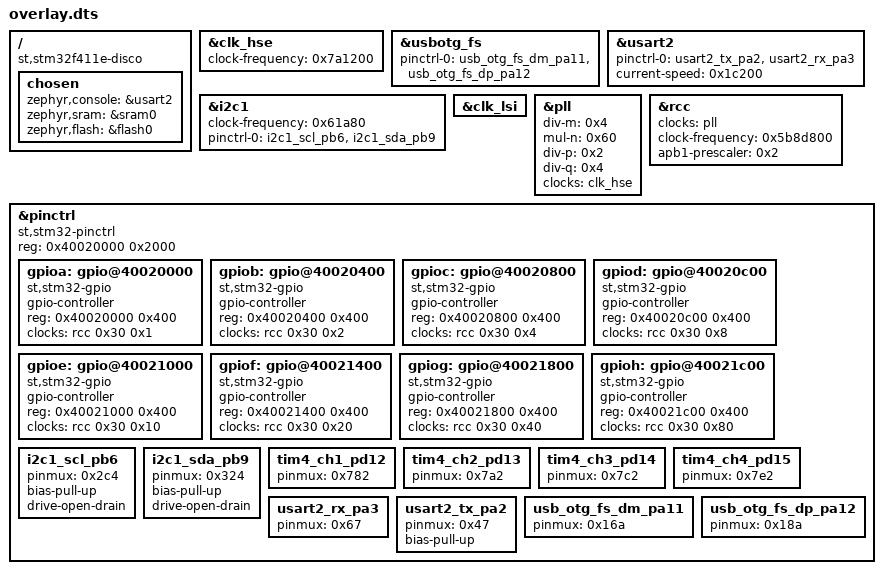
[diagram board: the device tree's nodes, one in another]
/ {
	compatible = "st,stm32f411e-disco";
	chosen {
		zephyr,console = &usart2;
		zephyr,sram = &sram0;
		zephyr,flash = &flash0;
	};
};
&clk_hse{
	status = "okay";
	clock-frequency = < 0x7a1200 >;
};
&usbotg_fs{
	status = "okay";
	pinctrl-0 = < &usb_otg_fs_dm_pa11 &usb_otg_fs_dp_pa12 >;
	pinctrl-names = "default";
};
&usart2{
	status = "okay";
	pinctrl-0 = < &usart2_tx_pa2 &usart2_rx_pa3 >;
	pinctrl-names = "default";
	current-speed = < 0x1c200 >;
};
&i2c1{
	clock-frequency = < 0x61a80 >;
	status = "okay";
	pinctrl-0 = < &i2c1_scl_pb6 &i2c1_sda_pb9 >;
	pinctrl-names = "default";
};
&clk_lsi{
	status = "okay";
};
&pll{
	status = "okay";
	div-m = < 0x4 >;
	mul-n = < 0x60 >;
	div-p = < 0x2 >;
	div-q = < 0x4 >;
	clocks = < &clk_hse >;
};
&rcc{
	clocks = < &pll >;
	clock-frequency = < 0x5b8d800 >;
	apb1-prescaler = < 0x2 >;
};
&pinctrl{
	compatible = "st,stm32-pinctrl";
	#address-cells = < 0x1 >;
	#size-cells = < 0x1 >;
	reg = < 0x40020000 0x2000 >;
	gpioa: gpio@40020000 {
		compatible = "st,stm32-gpio";
		gpio-controller;
		#gpio-cells = < 0x2 >;
		reg = < 0x40020000 0x400 >;
		clocks = < &rcc 0x30 0x1 >;
	};
	gpiob: gpio@40020400 {
		compatible = "st,stm32-gpio";
		gpio-controller;
		#gpio-cells = < 0x2 >;
		reg = < 0x40020400 0x400 >;
		clocks = < &rcc 0x30 0x2 >;
	};
	gpioc: gpio@40020800 {
		compatible = "st,stm32-gpio";
		gpio-controller;
		#gpio-cells = < 0x2 >;
		reg = < 0x40020800 0x400 >;
		clocks = < &rcc 0x30 0x4 >;
	};
	gpiod: gpio@40020c00 {
		compatible = "st,stm32-gpio";
		gpio-controller;
		#gpio-cells = < 0x2 >;
		reg = < 0x40020c00 0x400 >;
		clocks = < &rcc 0x30 0x8 >;
	};
	gpioe: gpio@40021000 {
		compatible = "st,stm32-gpio";
		gpio-controller;
		#gpio-cells = < 0x2 >;
		reg = < 0x40021000 0x400 >;
		clocks = < &rcc 0x30 0x10 >;
	};
	gpiof: gpio@40021400 {
		compatible = "st,stm32-gpio";
		gpio-controller;
		#gpio-cells = < 0x2 >;
		reg = < 0x40021400 0x400 >;
		clocks = < &rcc 0x30 0x20 >;
	};
	gpiog: gpio@40021800 {
		compatible = "st,stm32-gpio";
		gpio-controller;
		#gpio-cells = < 0x2 >;
		reg = < 0x40021800 0x400 >;
		clocks = < &rcc 0x30 0x40 >;
	};
	gpioh: gpio@40021c00 {
		compatible = "st,stm32-gpio";
		gpio-controller;
		#gpio-cells = < 0x2 >;
		reg = < 0x40021c00 0x400 >;
		clocks = < &rcc 0x30 0x80 >;
	};
	i2c1_scl_pb6: i2c1_scl_pb6 {
		pinmux = < 0x2c4 >;
		bias-pull-up;
		drive-open-drain;
	};
	i2c1_sda_pb9: i2c1_sda_pb9 {
		pinmux = < 0x324 >;
		bias-pull-up;
		drive-open-drain;
	};
	tim4_ch1_pd12: tim4_ch1_pd12 {
		pinmux = < 0x782 >;
	};
	tim4_ch2_pd13: tim4_ch2_pd13 {
		pinmux = < 0x7a2 >;
	};
	tim4_ch3_pd14: tim4_ch3_pd14 {
		pinmux = < 0x7c2 >;
	};
	tim4_ch4_pd15: tim4_ch4_pd15 {
		pinmux = < 0x7e2 >;
	};
	usart2_rx_pa3: usart2_rx_pa3 {
		pinmux = < 0x67 >;
	};
	usart2_tx_pa2: usart2_tx_pa2 {
		pinmux = < 0x47 >;
		bias-pull-up;
	};
	usb_otg_fs_dm_pa11: usb_otg_fs_dm_pa11 {
		pinmux = < 0x16a >;
	};
	usb_otg_fs_dp_pa12: usb_otg_fs_dp_pa12 {
		pinmux = < 0x18a >;
	};
};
